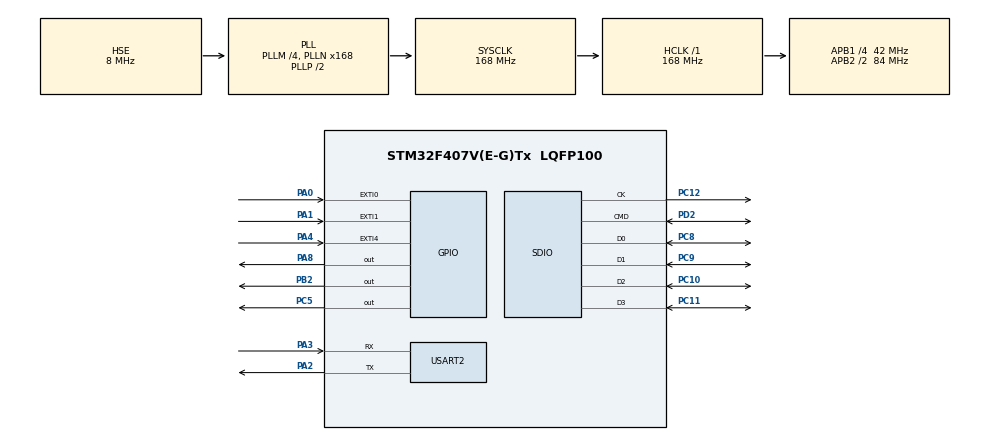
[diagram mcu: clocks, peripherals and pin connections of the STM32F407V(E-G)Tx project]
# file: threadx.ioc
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ADC1.Channel-0\#ChannelRegularConversion=ADC_CHANNEL_TEMPSENSOR
ADC1.Channel-1\#ChannelRegularConversion=ADC_CHANNEL_VREFINT
ADC1.ContinuousConvMode=ENABLE
ADC1.NbrOfConversion=2
ADC1.NbrOfConversionFlag=1
ADC1.Rank-0\#ChannelRegularConversion=1
ADC1.Rank-1\#ChannelRegularConversion=2
ADC1.SamplingTime-0\#ChannelRegularConversion=ADC_SAMPLETIME_480CYCLES
ADC1.SamplingTime-1\#ChannelRegularConversion=ADC_SAMPLETIME_480CYCLES
ADC1.master=1
Dma.ADC1.0.Direction=DMA_PERIPH_TO_MEMORY
Dma.ADC1.0.FIFOMode=DMA_FIFOMODE_DISABLE
Dma.ADC1.0.Instance=DMA2_Stream0
Dma.ADC1.0.MemDataAlignment=DMA_MDATAALIGN_HALFWORD
Dma.ADC1.0.MemInc=DMA_MINC_ENABLE
Dma.ADC1.0.Mode=DMA_CIRCULAR
Dma.ADC1.0.PeriphDataAlignment=DMA_PDATAALIGN_HALFWORD
Dma.ADC1.0.PeriphInc=DMA_PINC_DISABLE
Dma.ADC1.0.Priority=DMA_PRIORITY_MEDIUM
Dma.Request0=ADC1
Mcu.Family=STM32F4
Mcu.Name=STM32F407V(E-G)Tx
Mcu.Package=LQFP100
NVIC.ADC_IRQn=true\:1\:0\:true\:false\:true\:false\:true\:true\:true
NVIC.DMA2_Stream0_IRQn=true\:0\:0\:false\:false\:true\:true\:false\:true\:true
NVIC.EXTI0_IRQn=true\:2\:0\:true\:false\:true\:false\:true\:true\:true
NVIC.EXTI1_IRQn=true\:3\:0\:true\:false\:true\:false\:true\:true\:true
NVIC.EXTI4_IRQn=true\:2\:0\:true\:false\:true\:false\:true\:true\:true
NVIC.PriorityGroup=NVIC_PRIORITYGROUP_4
NVIC.TIM6_DAC_IRQn=true\:15\:0\:false\:false\:true\:false\:false\:true\:true
NVIC.TimeBase=TIM6_DAC_IRQn
NVIC.TimeBaseIP=TIM6
NVIC.USART2_IRQn=true\:0\:0\:true\:false\:true\:false\:true\:true\:true
PA0-WKUP.GPIO_PuPd=GPIO_PULLDOWN
PA0-WKUP.Signal=GPXTI0
PA1.GPIO_ModeDefaultEXTI=GPIO_MODE_IT_FALLING
PA1.GPIO_PuPd=GPIO_PULLUP
PA1.Signal=GPXTI1
PA2.Mode=Asynchronous
PA2.Signal=USART2_TX
PA3.Mode=Asynchronous
PA3.Signal=USART2_RX
PA4.GPIO_ModeDefaultEXTI=GPIO_MODE_IT_FALLING
PA4.GPIO_PuPd=GPIO_PULLUP
PA4.Signal=GPXTI4
PA8.GPIO_Speed=GPIO_SPEED_FREQ_HIGH
PA8.PinState=GPIO_PIN_SET
PA8.Signal=GPIO_Output
PB2.Signal=GPIO_Output
PC10.Mode=SD_4_bits_Wide_bus
PC10.Signal=SDIO_D2
PC11.Mode=SD_4_bits_Wide_bus
PC11.Signal=SDIO_D3
PC12.Mode=SD_4_bits_Wide_bus
PC12.Signal=SDIO_CK
PC5.Signal=GPIO_Output
PC8.Mode=SD_4_bits_Wide_bus
PC8.Signal=SDIO_D0
PC9.Mode=SD_4_bits_Wide_bus
PC9.Signal=SDIO_D1
PD2.Mode=SD_4_bits_Wide_bus
PD2.Signal=SDIO_CMD
PH0-OSC_IN.Mode=HSE-External-Oscillator
PH0-OSC_IN.Signal=RCC_OSC_IN
PH1-OSC_OUT.Mode=HSE-External-Oscillator
PH1-OSC_OUT.Signal=RCC_OSC_OUT
ProjectManager.HeapSize=0x200
ProjectManager.StackSize=0x400
ProjectManager.TargetToolchain=MDK-ARM V5.32
RCC.48MHZClocksFreq_Value=48000000
RCC.AHBFreq_Value=168000000
RCC.APB1CLKDivider=RCC_HCLK_DIV4
RCC.APB1Freq_Value=42000000
RCC.APB1TimFreq_Value=84000000
RCC.APB2CLKDivider=RCC_HCLK_DIV2
RCC.APB2Freq_Value=84000000
RCC.APB2TimFreq_Value=168000000
RCC.CortexFreq_Value=168000000
RCC.HCLKFreq_Value=168000000
RCC.HSE_VALUE=8000000
RCC.HSI_VALUE=16000000
RCC.LSE_VALUE=32768
RCC.PLLM=4
RCC.PLLN=168
RCC.PLLQ=7
RCC.PLLSourceVirtual=RCC_PLLSOURCE_HSE
RCC.SYSCLKFreq_VALUE=168000000
RCC.SYSCLKSource=RCC_SYSCLKSOURCE_PLLCLK
RCC.VCOOutputFreq_Value=336000000
SDIO.ClockDiv=1
STMicroelectronics.X-CUBE-AZRTOS-F4.1.1.0.TX_TIMER_TICKS_PER_SECOND=1000
STMicroelectronics.X-CUBE-AZRTOS-F4.1.1.0.ThreadXCcRTOSJjThreadXJjCore=true
STMicroelectronics.X-CUBE-AZRTOS-F4.1.1.0_IsAnAzureRtosMw=true
USART2.VirtualMode=VM_ASYNC
VP_ADC1_TempSens_Input.Mode=IN-TempSens
VP_ADC1_Vref_Input.Mode=IN-Vrefint
VP_STMicroelectronics.X-CUBE-AZRTOS-F4_VS_RTOSJjThreadX_6.1.10_1.1.0.Mode=RTOSJjThreadX
VP_SYS_VS_tim6.Mode=TIM6
board=custom

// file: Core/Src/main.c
/* USER CODE BEGIN Header */
/**
  ******************************************************************************
  * @file           : main.c
  * @brief          : Main program body
  ******************************************************************************
  * @attention
  *
  * Copyright (c) 2024 STMicroelectronics.
  * All rights reserved.
  *
  * This software is licensed under terms that can be found in the LICENSE file
  * in the root directory of this software component.
  * If no LICENSE file comes with this software, it is provided AS-IS.
  *
  ******************************************************************************
  */
/* USER CODE END Header */
#include "app_threadx.h"
#include "main.h"
#include "adc.h"
#include "dma.h"
#include "sdio.h"
#include "usart.h"
#include "gpio.h"

/* USER CODE BEGIN Includes */
#include "stdio.h"
/* USER CODE END Includes */

/* USER CODE BEGIN PD */
extern uint8_t Rarr[];
/* USER CODE END PD */

/* USER CODE BEGIN PV */
HAL_SD_CardInfoTypeDef pCardInfo;
/* USER CODE END PV */

void SystemClock_Config(void);

int main(void)
{

  /* MCU Configuration--------------------------------------------------------*/

  /* Reset of all peripherals, Initializes the Flash interface and the Systick. */
  HAL_Init();

  /* Configure the system clock */
  SystemClock_Config();

  /* Initialize all configured peripherals */
  MX_GPIO_Init();
  MX_DMA_Init();
  MX_USART2_UART_Init();
  MX_ADC1_Init();
  MX_SDIO_SD_Init();
  /* USER CODE BEGIN 2 */
	HAL_UARTEx_ReceiveToIdle_IT(&huart2,Rarr,20);
	HAL_GPIO_TogglePin(GPIOA,GPIO_PIN_8);
	printf("123");

  /* USER CODE END 2 */

  MX_ThreadX_Init();

  /* We should never get here as control is now taken by the scheduler */

  /* Infinite loop */
  while (1)
  {

  }
}

void SystemClock_Config(void)
{
  RCC_OscInitTypeDef RCC_OscInitStruct = {0};
  RCC_ClkInitTypeDef RCC_ClkInitStruct = {0};

  /** Configure the main internal regulator output voltage
  */
  __HAL_RCC_PWR_CLK_ENABLE();
  __HAL_PWR_VOLTAGESCALING_CONFIG(PWR_REGULATOR_VOLTAGE_SCALE1);

  /** Initializes the RCC Oscillators according to the specified parameters
  * in the RCC_OscInitTypeDef structure.
  */
  RCC_OscInitStruct.OscillatorType = RCC_OSCILLATORTYPE_HSE;
  RCC_OscInitStruct.HSEState = RCC_HSE_ON;
  RCC_OscInitStruct.PLL.PLLState = RCC_PLL_ON;
  RCC_OscInitStruct.PLL.PLLSource = RCC_PLLSOURCE_HSE;
  RCC_OscInitStruct.PLL.PLLM = 4;
  RCC_OscInitStruct.PLL.PLLN = 168;
  RCC_OscInitStruct.PLL.PLLP = RCC_PLLP_DIV2;
  RCC_OscInitStruct.PLL.PLLQ = 7;
  if (HAL_RCC_OscConfig(&RCC_OscInitStruct) != HAL_OK)
  {
    Error_Handler();
  }

  /** Initializes the CPU, AHB and APB buses clocks
  */
  RCC_ClkInitStruct.ClockType = RCC_CLOCKTYPE_HCLK|RCC_CLOCKTYPE_SYSCLK
                              |RCC_CLOCKTYPE_PCLK1|RCC_CLOCKTYPE_PCLK2;
  RCC_ClkInitStruct.SYSCLKSource = RCC_SYSCLKSOURCE_PLLCLK;
  RCC_ClkInitStruct.AHBCLKDivider = RCC_SYSCLK_DIV1;
  RCC_ClkInitStruct.APB1CLKDivider = RCC_HCLK_DIV4;
  RCC_ClkInitStruct.APB2CLKDivider = RCC_HCLK_DIV2;

  if (HAL_RCC_ClockConfig(&RCC_ClkInitStruct, FLASH_LATENCY_5) != HAL_OK)
  {
    Error_Handler();
  }
}

void HAL_TIM_PeriodElapsedCallback(TIM_HandleTypeDef *htim)
{
  if (htim->Instance == TIM6) {
    HAL_IncTick();
  }
}

void Error_Handler(void)
{
  __disable_irq();
  while (1)
  {
  }
}
